# RL6678_IP_SVD register map
Vendor: Realtek
Registers are 32-bit, read-write, reset 0x0 unless marked. A register's access mark holds for its fields unless they carry their own. Offsets are from the block's base; [hi:lo] are bit positions; {n}, {i} and the like mark numbered series.

## SPORT0_REG
Base 0x4100D000
Same registers: SPORT1_REG 0x4100E000, SPORT2_REG 0x4100F000, SPORT3_REG 0x41010000
0x00 SP_REG_MUX reset 0xFFFFFFFF — SPORT MUX Register
  [31:0] sp_reg_mux — Mux of register write with different base address of the same SPORT. "sp_reg_mux" can be set as different value with four different base address in one SPORT, but other registers share the same value with four different base addresses in one SPORT.
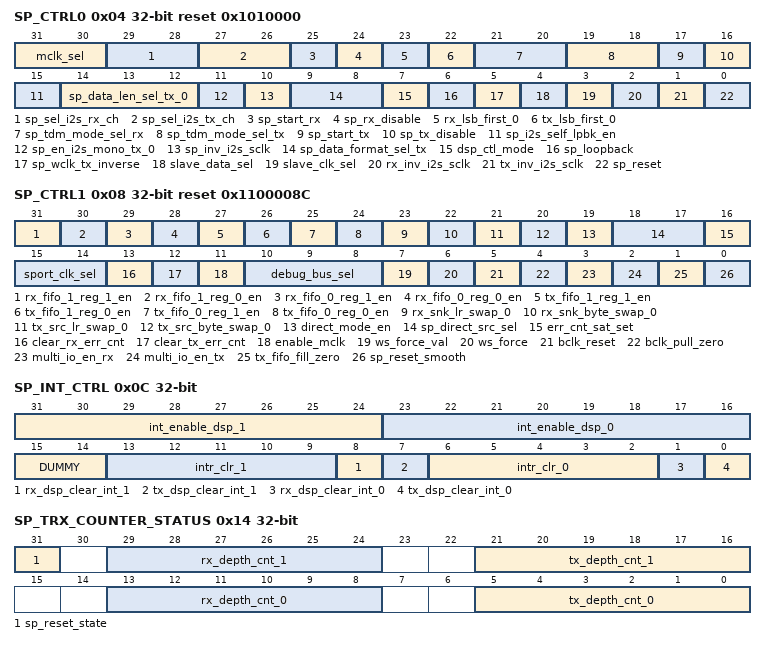
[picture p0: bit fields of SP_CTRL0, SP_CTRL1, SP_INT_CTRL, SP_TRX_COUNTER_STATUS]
0x04 SP_CTRL0 reset 0x1010000 — SPORT Control Register 0
  [31:30] mclk_sel — 2'b00: MCLK output=dsp_src_clk/4 2'b01: MCLK output=dsp_src_clk/2 2'b10/2'b11: MCLK output=dsp_src_clk
  [29:28] sp_sel_i2s_rx_ch — 2'b00: L/R 2'b01: R/L 2'b10: L/L 2'b11: R/R @ ADC path
  [27:26] sp_sel_i2s_tx_ch — 2'b00: L/R 2'b01: R/L 2'b10: L/L 2'b11: R/R @ DAC path
  [25] sp_start_rx — 1'b0: RX is disabled 1'b1: RX is started
  [24] sp_rx_disable — 1'b1: SPORT RX is disabled. 1'b0: SPORT RX is enabled.
  [23] rx_lsb_first_0 — 1'b0: MSB first when RX 1'b1: LSB first
  [22] tx_lsb_first_0 — 1'b0: MSB first when TX 1'b1: LSB first
  [21:20] sp_tdm_mode_sel_rx — 2'b00: Without TDM 2'b01: TDM4 2'b10: TDM6 2'b11: TDM8
  [19:18] sp_tdm_mode_sel_tx — 2'b00: Without TDM 2'b01: TDM4 2'b10: TDM6 2'b11: TDM8
  [17] sp_start_tx — 1'b0: TX is disabled. 1'b1: TX is started.
  [16] sp_tx_disable — 1'b1: SPORT TX is disabled. 1'b0: SPORT TX is enabled.
  [15] sp_i2s_self_lpbk_en — 1'b1: internal loopback mode is enabled
  [14:12] sp_data_len_sel_tx_0 — 3'b000: 16 bits 3'b001: 20 bits 3'b010: 24 bits 3'b100: 32 bits
  [11] sp_en_i2s_mono_tx_0 — 1'b1: mono 1'b0: stereo
  [10] sp_inv_i2s_sclk — 1'b1: I2S/PCM bit clock is inverted
  [9:8] sp_data_format_sel_tx — 2'b00: I2S 2'b01: Left Justified 2'b10: PCM mode A 2'b11: PCM mode B
  [7] dsp_ctl_mode — 1'b1: DSP and SPORT1 handshaking is enabled. 1'b0: GDMA and SPORT1 handshaking is enabled.
  [6] sp_loopback — 1'b1: Self-loopback mode
  [5] sp_wclk_tx_inverse — 1'b1: I2S/PCM word clock is inverted for TX (SPK path)
  [4] slave_data_sel — 1'b1: To be an I2S or PCM slave (data path)
  [3] slave_clk_sel — 1'b1: To be an I2S or PCM slave (CLK path)
  [2] rx_inv_i2s_sclk — 1'b1: sclk to RX path (ADC path) is inverted
  [1] tx_inv_i2s_sclk — 1'b1: sclk to TX path (DAC path) is inverted
  [0] sp_reset — 1'b1: Reset SPORT1 module, and remember to write "1" to reset and then write "0" to release from reset.
0x08 SP_CTRL1 access per field reset 0x1100008C — SPORT Control Register 1
  [31] rx_fifo_1_reg_1_en rw — 1'b1: Enable last two channel of RX_FIFO_1. Only enable when "rx_fifo_1_reg_0_en" = 1.
  [30] rx_fifo_1_reg_0_en rw — 1'b1: Enable first two channel of RX_FIFO_1. Only enable when "rx_fifo_0_reg_0_en" = 1.
  [29] rx_fifo_0_reg_1_en rw — 1'b1: Enable last two channel of RX_FIFO_0. Only enable when "rx_fifo_0_reg_0_en" = 1.
  [28] rx_fifo_0_reg_0_en rw — 1'b1: Enable first two channel of RX_FIFO_0. Disable 0x0008[28] ~ Disable 0x0008[31] at the same time to reset RX FIFO.
  [27] tx_fifo_1_reg_1_en rw — 1'b1: Enable last two channel of TX_FIFO_1. Only enable when "tx_fifo_1_reg_0_en" = 1.
  [26] tx_fifo_1_reg_0_en rw — 1'b1: Enable first two channel of TX_FIFO_1. Only enable when "tx_fifo_0_reg_0_en" = 1.
  [25] tx_fifo_0_reg_1_en rw — 1'b1: Enable last two channel of TX_FIFO_0. Only enable when "tx_fifo_0_reg_0_en" = 1.
  [24] tx_fifo_0_reg_0_en rw — 1'b1: Enable first two channel of TX_FIFO_0. Disable 0x0008[24] ~ 0x0008[27] at the same time to reset TX FIFO.
  [23] rx_snk_lr_swap_0 rw — 1'b1: Swap L/R audio samples written to the sink memory of RX_FIFO_0
  [22] rx_snk_byte_swap_0 rw — 1'b1: Swap H/L bytes written to the sink memory of RX_FIFO_0
  [21] tx_src_lr_swap_0 rw — 1'b1: Swap L/R audio samples read from the source memory of TX_FIFO_0
  [20] tx_src_byte_swap_0 rw — 1'b1: Swap H/L bytes read from the source memory of TX_FIFO_0
  [19] direct_mode_en rw — 1'b1: WS (LRCK) and SCK (BCLK) are from other SPORTs
  [18:17] sp_direct_src_sel rw — 2'b00: ws and sck are from SPORT0. 2'b01: ws and sck are from SPORT1. 2'b10: ws and sck are from SPORT2. 2'b11: ws and sck are from SPORT3.
  [16] err_cnt_sat_set rw — 1'b1: saturation count (65534 --> 65535 --> 65535 ...) 1'b0: wrap count (65534 --> 65535 --> 0 --> 1 --> 2 ...)
  [15:14] sport_clk_sel rw — 2'b0x00: dsp_src_clk (BCLK*2) 2'b10: dsp_src_clk (BCLK*4)/2 2'b11: dsp_src_clk (BCLK*8)/4
  [13] clear_rx_err_cnt rw — Write 1'b1 and then write 0 to clear Rx error counter
  [12] clear_tx_err_cnt rw — Write 1'b1 and then write 0 to clear Tx error counter
  [11] enable_mclk rw
  [10:8] debug_bus_sel rw — 3'b000: debug_bus_a 3'b001: debug_bus_b ... 3'b111: debug_bus_h
  [7] ws_force_val rw — When "ws_force" = 1, ws_out_tx and ws_out_rx = "ws_force_val"
  [6] ws_force rw — 1'b1: Make ws_out_tx and ws_out_rx = "ws_force_val"
  [5] bclk_reset rw — 1'b0: Enable bclk 1'b1: Disable and reset bclk
  [4] bclk_pull_zero rw — Write 1'b1 to pull bclk to 0 smoothly. Write 1'b0 to reopen bclk.
  [3] multi_io_en_rx rw — 1'b1: Enable multi-IO of Rx 1'b0: Disable multi-IO of Rx; SPORT2 & SPORT3 only.
  [2] multi_io_en_tx rw — 1'b1: Enable multi-IO of Tx 1'b0: Disable multi-IO of Tx; SPORT2 & SPORT3 only.
  [1] tx_fifo_fill_zero wo — X is the burst size of TX_FIFO_0. Y is the burst size of TX_FIFO_1. Fill TX_FIFO_0 with X zero data and fill TX_FIFO_1 with Y zero data. This control bit is "write 1 clear" type.
  [0] sp_reset_smooth rw — 1'b1: Reset SPORT1 module with complete LRCK cycle.
0x0C SP_INT_CTRL — SPORT Interrupt Control Register
  [31:24] int_enable_dsp_1 — Bit[24]: for the interrupt of "sp_ready_to_tx_1" Bit[25]: for the interrupt of "sp_ready_to_rx_1" Bit[26]: for the interrupt of "tx_fifo_full_intr_1" Bit[27]: for the interrupt of "rx_fifo_full_intr_1" Bit[28]: for the interrupt of "tx_fifo_empty_intr_1" Bit[29]: for the interrupt of "rx_fifo_empty_intr_1" Bit[30]: for the interrupt of "tx_i2s_idle_1" Bit[31]: Reserved
  [23:16] int_enable_dsp_0 — Bit[16]: for the interrupt of "sp_ready_to_tx" Bit[17]: for the interrupt of "sp_ready_to_rx" Bit[18]: for the interrupt of "tx_fifo_full_intr" Bit[19]: for the interrupt of "rx_fifo_full_intr" Bit[20]: for the interrupt of "tx_fifo_empty_intr" Bit[21]: for the interrupt of "rx_fifo_empty_intr" Bit[22]: for the interrupt of "tx_i2s_idle" Bit[23]: Reserved
  [15:14] DUMMY
  [13:9] intr_clr_1 — Bit[9]: for the interrupt of "tx_fifo_full_intr_1" Bit[10]: for the interrupt of "rx_fifo_full_intr_1" Bit[11]: for the interrupt of "tx_fifo_empty_intr_1" Bit[12]: for the interrupt of "rx_fifo_empty_intr_1" Bit[13]: Reserved
  [8] rx_dsp_clear_int_1 — For DSP mode (bypass GDMA), F/W writes 1'b1 and then 1'b0 to clear Rx interrupt. Note: Rx interrupt is to indicate that DSP can get audio data from RX FIFO_1
  [7] tx_dsp_clear_int_1 — For DSP mode (bypass GDMA), F/W writes 1'b1 and then 1'b0 to clear Tx interrupt. Note: Tx interrupt is to indicate that DSP can write audio data to TX FIFO_1
  [6:2] intr_clr_0 — Bit[2]: for the interrupt of "tx_fifo_full_intr" Bit[3]: for the interrupt of "rx_fifo_full_intr" Bit[4]: for the interrupt of "tx_fifo_empty_intr" Bit[5]: for the interrupt of "rx_fifo_empty_intr" Bit[6]: Reserved
  [1] rx_dsp_clear_int_0 — For DSP mode (bypass GDMA), F/W writes 1'b1 and then 1'b0 to clear Rx interrupt. Note: Rx interrupt is to indicate that DSP can get audio data from RX FIFO_0
  [0] tx_dsp_clear_int_0 — For DSP mode (bypass GDMA), F/W writes 1'b1 and then 1'b0 to clear Tx interrupt. Note: Tx interrupt is to indicate that DSP can write audio data to TX FIFO_0
0x14 SP_TRX_COUNTER_STATUS ro — SPORT TRX Counter Status Register
  [31] sp_reset_state — 1'b1: sp_reset is enabled. 1'b0: sp_reset is disabled.
  [29:24] rx_depth_cnt_1 — RX FIFO_1 depth counter status (MIC path)
  [21:16] tx_depth_cnt_1 — TX FIFO_1 depth counter status (SPK path)
  [13:8] rx_depth_cnt_0 — RX FIFO_0 depth counter status (MIC path)
  [5:0] tx_depth_cnt_0 — TX FIFO_0 depth counter status (SPK path)
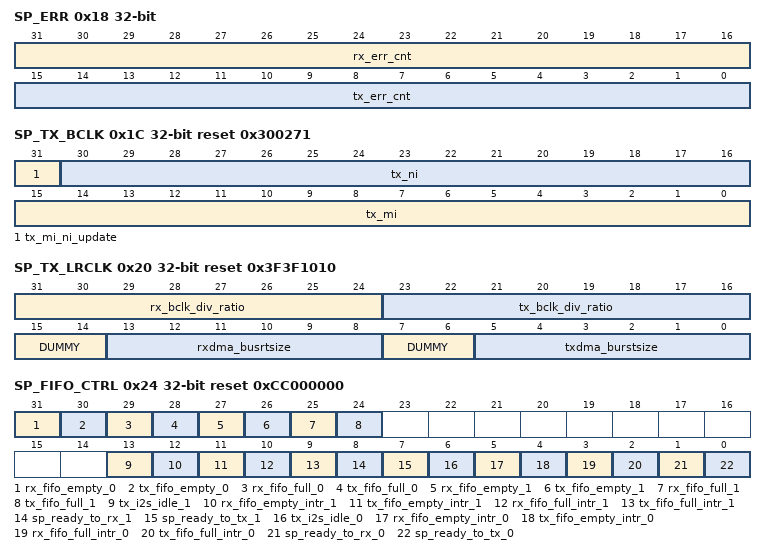
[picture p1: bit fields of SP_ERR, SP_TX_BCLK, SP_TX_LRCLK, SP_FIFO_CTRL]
0x18 SP_ERR ro — SPORT Error Register
  [31:16] rx_err_cnt — RX error counter (MIC path) Note: This counter should always be zero if everything works well.
  [15:0] tx_err_cnt — TX error counter (SPK path) Note: This counter should always be zero if everything works well.
0x1C SP_TX_BCLK reset 0x300271 — SPORT TX BCLK Register
  [31] tx_mi_ni_update — 1'b1: to update "mi" and "ni" to get the new clock rate. This bit will be reset automatically when the update is done.
  [30:16] tx_ni — BCLK = 40MHz*(ni/mi) For example: BCLK=3.072MHz=40MHz*(48/625)
  [15:0] tx_mi
0x20 SP_TX_LRCLK reset 0x3F3F1010 — SPORT TX LRCLK Register
  [31:24] rx_bclk_div_ratio — Rx bclk even-bit integer divider. Used in "mode_40mhz" set as 1'b1. (rx_bclk_div_ratio + 1) is the number of "sck_out" cycles within a "ws_out_rx" cycle (1/fs). Default of (rx_bclk_div_ratio + 1) is 64. Set as 64 - 1 = 63. Only odd number supported. Maximum is 255.
  [23:16] tx_bclk_div_ratio — Tx bclk even-bit integer divider. Used in "mode_40mhz" set as 1'b1. (tx_bclk_div_ratio + 1) is the number of "sck_out" cycles within a "ws_out_tx" cycle (1/fs). Default of (tx_bclk_div_ratio + 1) is 64. Set as 64 - 1 = 63. Only odd number supported. Maximum is 255.
  [15:14] DUMMY
  [13:8] rxdma_busrtsize — Rx DMA burst size
  [7:6] DUMMY
  [5:0] txdma_burstsize
0x24 SP_FIFO_CTRL ro reset 0xCC000000 — SPORT FIFO Control Register
  [31] rx_fifo_empty_0 — 1: RX FIFO_0 is empty.
  [30] tx_fifo_empty_0 — 1: TX FIFO_0 is empty.
  [29] rx_fifo_full_0 — 1: RX FIFO_0 is full.
  [28] tx_fifo_full_0 — 1: TX FIFO_0 is full.
  [27] rx_fifo_empty_1 — 1: RX FIFO_1 is empty.
  [26] tx_fifo_empty_1 — 1: TX FIFO_1 is empty.
  [25] rx_fifo_full_1 — 1: RX FIFO_1 is full.
  [24] tx_fifo_full_1 — 1: TX FIFO_1 is full.
  [13] tx_i2s_idle_1 — 1: TX is working but FIFO_1 is empty.
  [12] rx_fifo_empty_intr_1 — 1: RX FIFO_1 is empty (MIC path).
  [11] tx_fifo_empty_intr_1 — 1: TX FIFO_1 is empty (SPK path).
  [10] rx_fifo_full_intr_1 — 1: RX FIFO_1 is full (MIC path).
  [9] tx_fifo_full_intr_1 — 1: TX FIFO_1 is full (SPK path).
  [8] sp_ready_to_rx_1 — 1: It is ready to receive data (MIC path).
  [7] sp_ready_to_tx_1 — 1: It is ready to send data out (SPK path).
  [6] tx_i2s_idle_0 — 1: TX is working but FIFO_0 is empty.
  [5] rx_fifo_empty_intr_0 — 1: RX FIFO_0 is empty (MIC path).
  [4] tx_fifo_empty_intr_0 — 1: TX FIFO_0 is empty (SPK path).
  [3] rx_fifo_full_intr_0 — 1: RX FIFO_0 is full (MIC path).
  [2] tx_fifo_full_intr_0 — 1: TX FIFO_0 is full (SPK path).
  [1] sp_ready_to_rx_0 — 1: It is ready to receive data (MIC path).
  [0] sp_ready_to_tx_0 — 1: It is ready to send data out (SPK path).
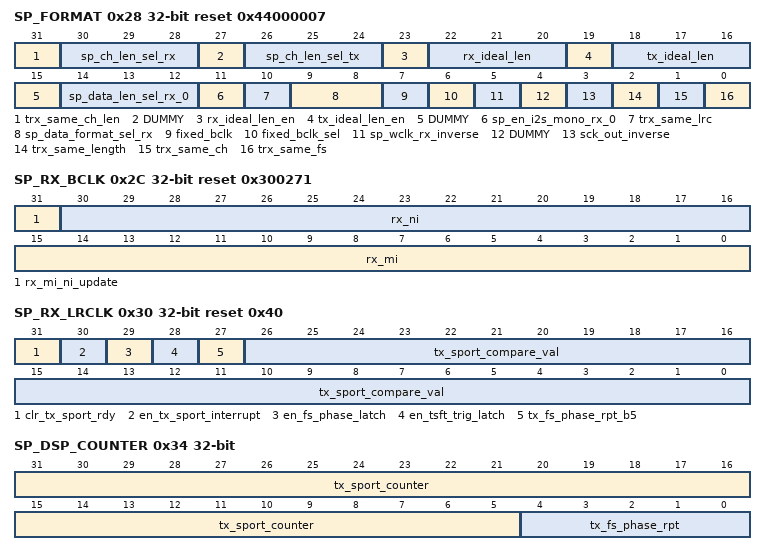
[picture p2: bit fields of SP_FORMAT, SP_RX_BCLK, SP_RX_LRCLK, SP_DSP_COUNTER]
0x28 SP_FORMAT reset 0x44000007 — SPORT Format Register
  [31] trx_same_ch_len — 1: TX (SPK path) and RX (MIC path) have the same channel length.
  [30:28] sp_ch_len_sel_rx — 3'b000: 16 bits 3'b001: 20 bits 3'b010: 24 bits 3'b100: 32 bits
  [27] DUMMY
  [26:24] sp_ch_len_sel_tx — 3'b000: 16 bits 3'b001: 20 bits 3'b010: 24 bits 3'b100: 32 bits
  [23] rx_ideal_len_en — Function enable of rx_ideal_len.
  [22:20] rx_ideal_len — sd_in can be received 1 ~ 8 ( = rx_ideal_len + 1 ) BCLK cycle latter.
  [19] tx_ideal_len_en — Function enable of tx_ideal_len. PCMA SDO will be delayed 1 LRCK.
  [18:16] tx_ideal_len — sd_out can be sent 1 ~ 8 ( = tx_ideal_len + 1 ) BCLK cycle earlier.
  [15] DUMMY
  [14:12] sp_data_len_sel_rx_0 — Data length of MIC path and it is valid if "trx_same_length" == 1'b0. 3'b000: 16 bits 3'b001: 20 bits 3'b010: 24 bits 3'b100: 32 bits
  [11] sp_en_i2s_mono_rx_0 — Channel format of MIC path and it is valid if "trx_same_ch" == 1'b0. 1: mono 0: stereo
  [10] trx_same_lrc — 1: "ws_out_rx" is the same as "ws_out_tx".
  [9:8] sp_data_format_sel_rx — Data format of MIC path and it is valid if "trx_same_fs" == 1'b0. 2'b00: I2S 2'b01: Left Justified 2'b10: PCM mode A 2'b11: PCM mode B
  [7] fixed_bclk — 1: Refer to the description of "fixed_bclk_sel" 0: BCLK = dsp_clk/2 when "mode_40mhz = 0"
  [6] fixed_bclk_sel — 0: BCLK is fixed at dsp_src_clk/4 1: BCLK is fixed at dsp_src_clk/2
  [5] sp_wclk_rx_inverse — 1: Invert the phase of "ws_out_rx" which is also called as "ADCLRC"
  [4] DUMMY
  [3] sck_out_inverse — 1: Invert the phase of "sck_out"
  [2] trx_same_length — 1: TX (SPK path) and RX (MIC path) have the same data length. Both are either 16 or 24 bits
  [1] trx_same_ch — 1: TX (SPK path) and RX (MIC path) have the same channel setting. Both are either stereo or mono
  [0] trx_same_fs — 1: TX (SPK path) and RX (MIC path) have the same sampling rate.
0x2C SP_RX_BCLK reset 0x300271 — SPORT RX BCLK Register
  [31] rx_mi_ni_update — 1'b1: to update "mi" and "ni" to get the new clock rate. This bit will be reset automatically when the update is done.
  [30:16] rx_ni — BCLK = 40MHz*(ni/mi) For example: BCLK=3.072MHz=40MHz*(48/625)
  [15:0] rx_mi
0x30 SP_RX_LRCLK access per field reset 0x40 — SPORT RX LRCLK Register
  [31] clr_tx_sport_rdy wo — 0x001: clear tx_sport_interrupt signal This control bit is "write 1 clear" type. For read, the read data is from clr_tx_sport_rdy.
  [30] en_tx_sport_interrupt rw — Enable tx_sport_interrupt
  [29] en_fs_phase_latch wo — 0x001: Latch the value of tx_fs_phase_rpt, rx_fs_phase_rpt, tx_sport_sounter, rx_sport_sounter at the same time. This control bit is "write 1 clear" type.
  [28] en_tsft_trig_latch rw — Enable Wi-Fi tsft trigger fs_phase_latch
  [27] tx_fs_phase_rpt_b5 ro — tx_fs_phase_rptp[5] when using div64 fs_phase_trace_cnt
  [26:0] tx_sport_compare_val rw — X = tx_sport_compare_val When counter equal X, SPORT will send tx_sport_interrupt to DSP. FW should take care X={32~134217727}
0x34 SP_DSP_COUNTER ro — SPORT DSP Counter Register
  [31:5] tx_sport_counter — For DSP read instant Tx sport counter value, counter down
  [4:0] tx_fs_phase_rpt — Report Tx phase
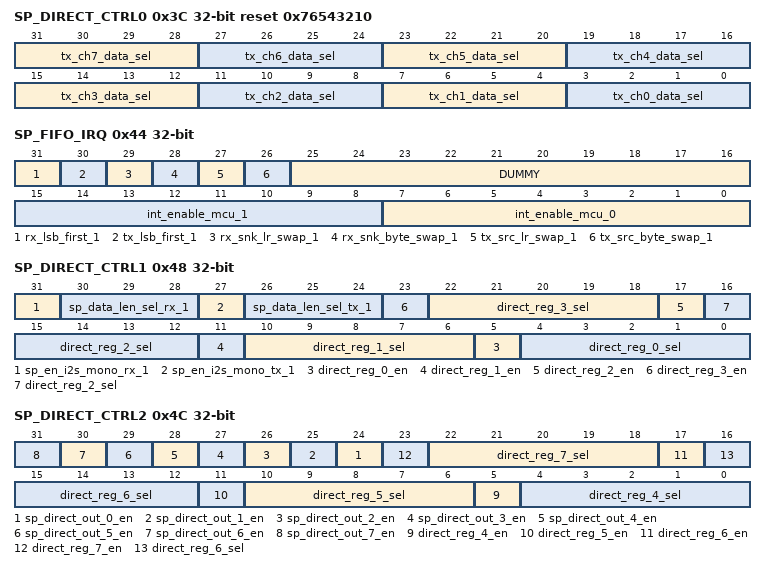
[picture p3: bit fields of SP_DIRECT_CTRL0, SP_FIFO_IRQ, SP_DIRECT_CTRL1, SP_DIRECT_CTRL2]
0x3C SP_DIRECT_CTRL0 reset 0x76543210 — SPORT Direct Control Register 0
  [31:28] tx_ch7_data_sel — 4'h0: tx_fifo_0_reg_0_l 4'h1: tx_fifo_0_reg_0_r 4'h2: tx_fifo_0_reg_1_l 4'h3: tx_fifo_0_reg_1_r 4'h4: tx_fifo_1_reg_0_l 4'h5: tx_fifo_1_reg_0_r 4'h6: tx_fifo_1_reg_1_l 4'h7: tx_fifo_1_reg_1_r 4'h8: direct_reg_7
  [4n+3:4n] tx_ch{n}_data_sel (n=0..6) — (Ibid.) 4'h8: direct_reg_{n}
0x44 SP_FIFO_IRQ — SPORT FIFO IRQ Register
  [31] rx_lsb_first_1 — 1'b0: MSB first when TX 1'b1: LSB first
  [30] tx_lsb_first_1 — 1'b0: MSB first when TX 1'b1: LSB first
  [29] rx_snk_lr_swap_1 — 1'b1: swap L/R audio samples written to the sink memory of RX_FIFO_1
  [28] rx_snk_byte_swap_1 — 1'b1: swap H/L bytes written to the sink memory of RX_FIFO_1
  [27] tx_src_lr_swap_1 — 1'b1: swap L/R audio samples read from the source memory of TX_FIFO_1
  [26] tx_src_byte_swap_1 — 1'b1: swap H/L bytes read from the source memory of TX_FIFO_1
  [25:16] DUMMY
  [15:8] int_enable_mcu_1 — Bit[8]: for the interrupt of "sp_ready_to_tx" Bit[9]: for the interrupt of "sp_ready_to_rx" Bit[10]: for the interrupt of "tx_fifo_full_intr" Bit[11]: for the interrupt of "rx_fifo_full_intr" Bit[12]: for the interrupt of "tx_fifo_empty_intr" Bit[13]: for the interrupt of "rx_fifo_empty_intr" Bit[14]: for the interrupt of "tx_i2s_idle" Bit[15]: Reserved
  [7:0] int_enable_mcu_0 — Bit[0]: for the interrupt of "sp_ready_to_tx" Bit[1]: for the interrupt of "sp_ready_to_rx" Bit[2]: for the interrupt of "tx_fifo_full_intr" Bit[3]: for the interrupt of "rx_fifo_full_intr" Bit[4]: for the interrupt of "tx_fifo_empty_intr" Bit[5]: for the interrupt of "rx_fifo_empty_intr" Bit[6]: for the interrupt of "tx_i2s_idle" Bit[7]: Reserved
0x48 SP_DIRECT_CTRL1 — SPORT Direct Control Register 1
  [31] sp_en_i2s_mono_rx_1 — Channel format of MIC path and it is valid if "trx_same_ch" == 1'b0. 1'b1: mono 1'b0: stereo
  [30:28] sp_data_len_sel_rx_1 — Data length of MIC path and it is valid if "trx_same_length" == 1'b0. 3'b000: 16 bits 3'b001: 20 bits 3'b010: 24 bits 3'b100: 32 bits
  [27] sp_en_i2s_mono_tx_1 — 1'b1: mono 1'b0: stereo
  [26:24] sp_data_len_sel_tx_1 — 3'b000: 16 bits 3'b001: 20 bits 3'b010: 24 bits 3'b100: 32 bits
  [6n+5] direct_reg_{n}_en (n=0..3) — 1'b1: Enable direct_reg_{n}.
  [22:18] direct_reg_3_sel — 5'h0: spa_direct_in_0 5'h1: spa_direct_in_1 5'h2: spa_direct_in_2 5'h3: spa_direct_in_3 5'h4: spa_direct_in_4 5'h5: spa_direct_in_5 5'h6: spa_direct_in_6 5'h7: spa_direct_in_7 5'h8: spb_direct_in_0 5'h9: spb_direct_in_1 5'ha: spb_direct_in_2 5'hb: spb_direct_in_3 5'hc: spb_direct_in_4 5'hd: spb_direct_in_5 5'he: spb_direct_in_6 5'hf: spb_direct_in_7 5'h10: spc_direct_in_0 5'h11: spc_direct_in_1 5'h12: spc_direct_in_2 5'h13: spc_direct_in_3 5'h14: spc_direct_in_4 5'h15: spc_direct_in_5 5'h16: spc_direct_in_6 5'h17: spc_direct_in_7 5'h18: sp0_direct_in_tx_fifo_0_reg_0_l 5'h19: sp0_direct_in_tx_fifo_0_reg_0_r 5'h1a: sp0_direct_in_tx_fifo_0_reg_1_l 5'h1b: sp0_direct_in_tx_fifo_0_reg_1_r 5'h1c: TDM_RX_CH3 SPORT0: a = 1, b = 2, c = 3 SPORT1: a = 0, b = 2, c = 3 SPORT2: a = 0, b = 1, c = 3 SPORT3: a = 0, b = 1, c = 2
  [16:12] direct_reg_2_sel — (Ibid.) 5'h1c: TDM_RX_CH2
  [10:6] direct_reg_1_sel — (Ibid.) 5'h1c: TDM_RX_CH1
  [4:0] direct_reg_0_sel — (Ibid.) 5'h1c: TDM_RX_CH0
0x4C SP_DIRECT_CTRL2 — SPORT Direct Control Register 2
  [n+24] sp_direct_out_{n}_en (n=0..7) — Enable sp_direct_out_{n}.
  [6n-19] direct_reg_{n}_en (n=4..7) — 1'b1: Enable direct_reg_{n}.
  [22:18] direct_reg_7_sel — 5'h0: spa_direct_in_0 5'h1: spa_direct_in_1 5'h2: spa_direct_in_2 5'h3: spa_direct_in_3 5'h4: spa_direct_in_4 5'h5: spa_direct_in_5 5'h6: spa_direct_in_6 5'h7: spa_direct_in_7 5'h8: spb_direct_in_0 5'h9: spb_direct_in_1 5'ha: spb_direct_in_2 5'hb: spb_direct_in_3 5'hc: spb_direct_in_4 5'hd: spb_direct_in_5 5'he: spb_direct_in_6 5'hf: spb_direct_in_7 5'h10: spc_direct_in_0 5'h11: spc_direct_in_1 5'h12: spc_direct_in_2 5'h13: spc_direct_in_3 5'h14: spc_direct_in_4 5'h15: spc_direct_in_5 5'h16: spc_direct_in_6 5'h17: spc_direct_in_7 5'h18: sp0_direct_in_tx_fifo_0_reg_0_l 5'h19: sp0_direct_in_tx_fifo_0_reg_0_r 5'h1a: sp0_direct_in_tx_fifo_0_reg_1_l 5'h1b: sp0_direct_in_tx_fifo_0_reg_1_r 5'h1c: TDM_RX_CH7 SPORT0: a = 1, b = 2, c = 3 SPORT1: a = 0, b = 2, c = 3 SPORT2: a = 0, b = 1, c = 3 SPORT3: a = 0, b = 1, c = 2
  [16:12] direct_reg_6_sel — (Ibid.) 5'h1c: TDM_RX_CH6
  [10:6] direct_reg_5_sel — (Ibid.) 5'h1c: TDM_RX_CH5
  [4:0] direct_reg_4_sel — (Ibid.) 5'h1c: TDM_RX_CH4
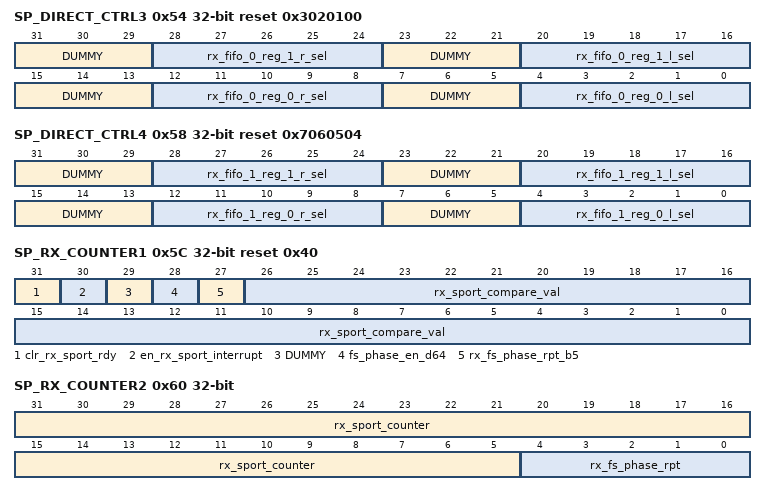
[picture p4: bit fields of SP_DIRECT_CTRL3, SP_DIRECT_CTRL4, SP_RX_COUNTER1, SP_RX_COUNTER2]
0x54 SP_DIRECT_CTRL3 reset 0x3020100 — SPORT Direct Control Register 3
  [31:29] DUMMY
  [28:24] rx_fifo_0_reg_1_r_sel — 5'd0: RX_CH0_data_out (MIC path) 5'd1: RX_CH1_data_out (MIC path) 5'd2: RX_CH2_data_out (MIC path) 5'd3: RX_CH3_data_out (MIC path) 5'd4: RX_CH4_data_out (MIC path) 5'd5: RX_CH5_data_out (MIC path) 5'd6: RX_CH6_data_out (MIC path) 5'd7: RX_CH7_data_out (MIC path) 5'd8: spa_direct_in_0 5'd9: spa_direct_in_1 5'd10: spa_direct_in_2 5'd11: spa_direct_in_3 5'd12: spa_direct_in_4 5'd13: spa_direct_in_5 5'd14: spa_direct_in_6 5'd15: spa_direct_in_7 5'd16: spb_direct_in_0 5'd17: spb_direct_in_1 5'd18: spb_direct_in_2 5'd19: spb_direct_in_3 5'd20: spb_direct_in_4 5'd21: spb_direct_in_5 5'd22: spb_direct_in_6 5'd23: spb_direct_in_7 5'd24: spc_direct_in_0 5'd25: spc_direct_in_1 5'd26: spc_direct_in_2 5'd27: spc_direct_in_3 5'd28: spc_direct_in_4 5'd29: spc_direct_in_5 5'd30: spc_direct_in_6 5'd31: spc_direct_in_7 SPORT0: a = 1, b = 2, c = 3 SPORT1: a = 0, b = 2, c = 3 SPORT2: a = 0, b = 1, c = 3 SPORT3: a = 0, b = 1, c = 2
  [23:21] DUMMY
  [20:16] rx_fifo_0_reg_1_l_sel — (Ibid.)
  [15:13] DUMMY
  [12:8] rx_fifo_0_reg_0_r_sel — (Ibid.)
  [7:5] DUMMY
  [4:0] rx_fifo_0_reg_0_l_sel — (Ibid.)
0x58 SP_DIRECT_CTRL4 reset 0x7060504 — SPORT Direct Control Register 4
  [31:29] DUMMY
  [28:24] rx_fifo_1_reg_1_r_sel — 5'd0: RX_CH0_data_out (MIC path) 5'd1: RX_CH1_data_out (MIC path) 5'd2: RX_CH2_data_out (MIC path) 5'd3: RX_CH3_data_out (MIC path) 5'd4: RX_CH4_data_out (MIC path) 5'd5: RX_CH5_data_out (MIC path) 5'd6: RX_CH6_data_out (MIC path) 5'd7: RX_CH7_data_out (MIC path) 5'd8: spa_direct_in_0 5'd9: spa_direct_in_1 5'd10: spa_direct_in_2 5'd11: spa_direct_in_3 5'd12: spa_direct_in_4 5'd13: spa_direct_in_5 5'd14: spa_direct_in_6 5'd15: spa_direct_in_7 5'd16: spb_direct_in_0 5'd17: spb_direct_in_1 5'd18: spb_direct_in_2 5'd19: spb_direct_in_3 5'd20: spb_direct_in_4 5'd21: spb_direct_in_5 5'd22: spb_direct_in_6 5'd23: spb_direct_in_7 5'd24: spc_direct_in_0 5'd25: spc_direct_in_1 5'd26: spc_direct_in_2 5'd27: spc_direct_in_3 5'd28: spc_direct_in_4 5'd29: spc_direct_in_5 5'd30: spc_direct_in_6 5'd31: spc_direct_in_7 SPORT0: a = 1, b = 2, c = 3 SPORT1: a = 0, b = 2, c = 3 SPORT2: a = 0, b = 1, c = 3 SPORT3: a = 0, b = 1, c = 2
  [23:21] DUMMY
  [20:16] rx_fifo_1_reg_1_l_sel — (Ibid.)
  [15:13] DUMMY
  [12:8] rx_fifo_1_reg_0_r_sel — (Ibid.)
  [7:5] DUMMY
  [4:0] rx_fifo_1_reg_0_l_sel — (Ibid.)
0x5C SP_RX_COUNTER1 access per field reset 0x40 — SPORT RX Counter Register 1
  [31] clr_rx_sport_rdy wo — X = tx_sport_compare_val When counter equal X, SPORT will send tx_sport_interrupt to DSP. FW should take care X={32~8191}
  [30] en_rx_sport_interrupt rw — Enable rx sport interrupt.
  [29] DUMMY rw
  [28] fs_phase_en_d64 rw — Enable div64 fs_phase_trace_cnt for both tx and rx
  [27] rx_fs_phase_rpt_b5 ro — rx_fs_phase_rptp[5] when using div64 fs_phase_trace_cnt
  [26:0] rx_sport_compare_val rw — X = rx_sport_compare_val When counter equal X, SPORT will send rx_sport_interrupt to DSP. FW should take care X={32~134217727}
0x60 SP_RX_COUNTER2 ro — SPORT RX Counter Register 2
  [31:5] rx_sport_counter — For DSP read instant rx sport counter value, counter down
  [4:0] rx_fs_phase_rpt — Report Rx phase
0x800 TX_FIFO_0_WR_ADDR wo — TX FIFO 0 Write Address Register
  [31:0] TX_FIFO_0_WR_ADDR — TX FIFO 0 Write Address
0x880 RX_FIFO_0_RD_ADDR ro — RX FIFO 0 Read Address Register
  [31:0] RX_FIFO_0_RD_ADDR — RX FIFO 0 Read Address
0x900 TX_FIFO_1_WR_ADDR wo — TX FIFO 1 Write Address Register
  [31:0] TX_FIFO_1_WR_ADDR — TX FIFO 1 Write Address
0x980 RX_FIFO_1_RD_ADDR ro — RX FIFO 1 Read Address Register
  [31:0] RX_FIFO_1_RD_ADDR — RX FIFO 1 Read Address
